AUTOSAR XML (schema 4-0-3)
standard types defined: Boolean, UInt16
package /AUTOSAR_Platform/DataConstrs
  range DC_Boolean: raw 0..1
  range DC_UInt16: raw 0..65535
package /PATAC/MSM/ComponentTypes
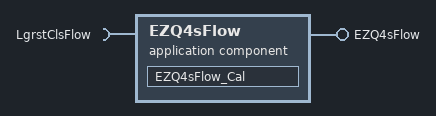
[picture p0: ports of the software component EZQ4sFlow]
  application sw component type EZQ4sFlow
    provide port EZQ4sFlow: server-com-spec{operation=EZQ4sFlow/Cal, queue-length=1}, provided-interface=EZQ4sFlow
    require port LgrstClsFlow: client-com-spec=LgrstClsFlow/Cal, required-interface=LgrstClsFlow
    behavior EZQ4sFlow_InternalBehavior
      operation invoked event OIT_EZQ4sFlow_Cal_EZQ4sFlow_Cal: start-on-event=EZQ4sFlow_Cal, operation=EZQ4sFlow.Cal
      runnable EZQ4sFlow_Cal
        sync call SC_LgrstClsFlow_Cal: operation=LgrstClsFlow.Cal, timeout=0
  swc implementation EZQ4sFlow_Implementation: behavior=EZQ4sFlow_InternalBehavior
    code-descriptors:
      code Default: artifact-descriptors=autosar-engineering-object={short-label=Default, category=SWSRC}
package /PATAC/MSM/ModeAdjust/PortInterface
  client server interface EZQ4sFlow
    operation Cal
      20 x arg, all with server-argument-impl-policy=USE-ARGUMENT-TYPE:
        LgrstUpwdDnwdPos: type=UInt16, direction=IN
        LgrstOtwdInwdPos: type=UInt16, direction=IN
        FtUpwdDnwdPos: type=UInt16, direction=IN
        CloseDnwdPos1: type=UInt16, direction=IN
        CloseDnwdPos2: type=UInt16, direction=IN
        CloseOtwdPos1: type=UInt16, direction=IN
        LgrstInwdStgDone: type=Implementation/Boolean, direction=IN
        LgrstUpwdStgDone: type=Implementation/Boolean, direction=IN
        FtrstStgDone: type=Implementation/Boolean, direction=IN
        FrwdBkwdStgDone: type=DataTypes/Boolean, direction=IN
        BkReclnStgDone: type=DataTypes/Boolean, direction=IN
        StEmpty: type=DataTypes/Boolean, direction=IN
        Failflg: type=Implementation/Boolean, direction=OUT
        LgrstInwdOtwdEn: type=Implementation/Boolean, direction=OUT
        LgrstUpwdDnwdEn: type=Implementation/Boolean, direction=OUT
        FtrstEn: type=Implementation/Boolean, direction=OUT
        FrwdBkwdEn: type=DataTypes/Boolean, direction=OUT
        BkReclnEn: type=DataTypes/Boolean, direction=OUT
        WaitComplete: type=DataTypes/Boolean, direction=IN
        RetryStFlg: type=DataTypes/Boolean, direction=OUT
  client server interface LgrstClsFlow
    operation Cal
      13 x arg, all with server-argument-impl-policy=USE-ARGUMENT-TYPE:
        LgrstUpwdDnwdPos: type=UInt16, direction=IN
        LgrstOtwdInwdPos: type=UInt16, direction=IN
        FtUpwdDnwdPos: type=UInt16, direction=IN
        CloseDnwdPos1: type=UInt16, direction=IN
        CloseDnwdPos2: type=UInt16, direction=IN
        CloseOtwdPos1: type=UInt16, direction=IN
        LgrstInwdStgDone: type=Implementation/Boolean, direction=IN
        LgrstUpwdStgDone: type=Implementation/Boolean, direction=IN
        FtrstStgDone: type=Implementation/Boolean, direction=IN
        Failflg: type=Implementation/Boolean, direction=OUT
        LgrstInwdOtwdEn: type=Implementation/Boolean, direction=OUT
        LgrstUpwdDnwdEn: type=Implementation/Boolean, direction=OUT
        FtrstEn: type=Implementation/Boolean, direction=OUT
